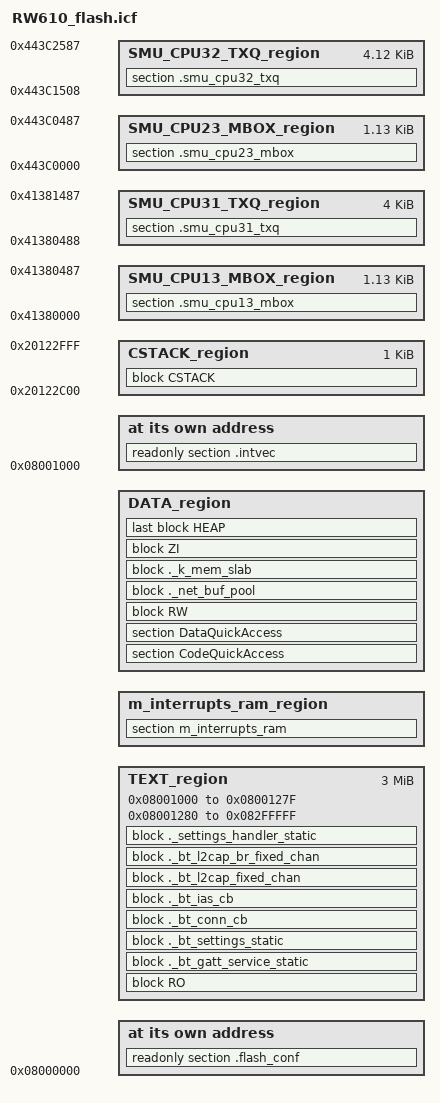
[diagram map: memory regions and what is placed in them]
/*
** ###################################################################
**     Processors:          RW612ETA2I
**                          RW612HNA2I
**                          RW612UKA2I
**
**     Compiler:            IAR ANSI C/C++ Compiler for ARM
**     Reference manual:    RW61X User manual Rev. 0.95, June 2022
**     Version:             rev. 1.0, 2021-03-16
**     Build:               b231201
**
**     Abstract:
**         Linker file for the IAR ANSI C/C++ Compiler for ARM
**
**     Copyright 2016 Freescale Semiconductor, Inc.
**     Copyright 2016-2023 NXP
**     SPDX-License-Identifier: BSD-3-Clause
**
**     http:                 www.nxp.com
**     mail:                 support@nxp.com
**
** ###################################################################
*/

/* Stack and Heap Sizes */
if (isdefinedsymbol(__stack_size__)) {
  define symbol __size_cstack__        = __stack_size__;
} else {
  define symbol __size_cstack__        = 0x0400;
}

if (isdefinedsymbol(__heap_size__)) {
  define symbol __size_heap__          = __heap_size__;
} else {
  define symbol __size_heap__          = 0x0400;
}

define symbol __ram_vector_table_size__        =  isdefinedsymbol(__ram_vector_table__) ? 0x00000280 : 0;
define symbol __ram_vector_table_offset__      =  isdefinedsymbol(__ram_vector_table__) ? 0x0000027F : 0;

define symbol m_interrupts_start               = 0x08001000;
define symbol m_interrupts_end                 = 0x0800127F;

define symbol m_text_start                     = 0x08001280;
define symbol m_text_end                       = 0x082FFFFF;

define symbol m_interrupts_ram_start           = 0x20000000;
define symbol m_interrupts_ram_end             = 0x20000000 + __ram_vector_table_offset__;

define symbol m_data_start                     = m_interrupts_ram_start + __ram_vector_table_size__;
define symbol m_data_end                       = 0x20122FFF;
/* 0x2012_3000 - 0x2012_FFFF is reserved for RW610 A1 BootROM code*/

define symbol m_boot_flash_start               = 0x08000000;

define symbol m_mbox13_start                   = 0x41380000;
define symbol m_mbox13_end                     = 0x41380487;

define symbol m_txq31_start                    = 0x41380488;
define symbol m_txq31_end                      = 0x41381487;

define symbol m_mbox23_start                   = 0x443C0000;
define symbol m_mbox23_end                     = 0x443C0487;

define symbol m_txq23_start                    = 0x443C0488;
define symbol m_txq23_end                      = 0x443C1507;

define symbol m_txq32_start                    = 0x443C1508;
define symbol m_txq32_end                      = 0x443C2587;

define exported symbol __VECTOR_TABLE          = m_interrupts_start;
define exported symbol __VECTOR_RAM            = isdefinedsymbol(__ram_vector_table__) ? m_interrupts_ram_start : m_interrupts_start;
define exported symbol __RAM_VECTOR_TABLE_SIZE = __ram_vector_table_size__;

define memory mem with size = 4G;

define symbol LITTLEFS_REGION_SIZE             = 0x00200000;

/* NOTE: The last LITTLEFS_REGION_SIZE Flash( in range (m_text_end + 1) ~ (m_text_end + LITTLEFS_REGION_SIZE)) is reserved for litteFS data */

/*** littleFS configuration Start ***/
define exported symbol EDGEFAST_BT_LITTLEFS_STORAGE_START_ADDRESS = m_text_end + 1;
define exported symbol EDGEFAST_BT_LITTLEFS_STORAGE_SECTOR_SIZE   = 0x1000;  /* 4k flash sector size */
define exported symbol EDGEFAST_BT_LITTLEFS_STORAGE_MAX_SECTORS   = LITTLEFS_REGION_SIZE / EDGEFAST_BT_LITTLEFS_STORAGE_SECTOR_SIZE;
/*** littleFS configuration End ***/

define region TEXT_region             = mem:[from m_interrupts_start to m_interrupts_end]
                                      | mem:[from m_text_start to m_text_end];
define region m_interrupts_ram_region = mem:[from m_interrupts_ram_start to m_interrupts_ram_end];
define region DATA_region             = mem:[from m_data_start to m_data_end - __size_cstack__];
define region CSTACK_region           = mem:[from m_data_end-__size_cstack__ + 1 to m_data_end];
define region SMU_CPU13_MBOX_region   = mem:[from m_mbox13_start to m_mbox13_end];
define region SMU_CPU31_TXQ_region    = mem:[from m_txq31_start to m_txq31_end];
define region SMU_CPU23_MBOX_region   = mem:[from m_mbox23_start to m_mbox23_end];
define region SMU_CPU32_TXQ_region    = mem:[from m_txq32_start to m_txq32_end];

define block CSTACK    with alignment = 8, size = __size_cstack__   { };
define block HEAP      with alignment = 8, size = __size_heap__     { };
define block RO        { readonly };
define block RW        { readwrite };
define block ZI        { zi };

initialize by copy {
  readwrite,
  section .textrw,
  section CodeQuickAccess,
  section DataQuickAccess,
  object port.o,
  object portasm.o,
  object queue.o,
  object timers.o,
  object tasks.o,
  object inet_chksum.o,
  object ip4.o,
  object pbuf.o,
  object sys_arch.o,
  object tcp_out.o,
  object tcp_in.o,
  object mlan_11n_rxreorder.o,
  object mlan_wmm.o,
  object wifi.o,
  object wifi-imu.o,
  object fsl_adapter_rfimu.o,
  object fsl_cache.o,
  object fsl_os_abstraction_free_rtos.o,
  object fsl_flexspi.o,
  object mflash_drv.o,
  object lfs.o,
  object littlefs_adapter.o
};

do not initialize  { section .noinit, section .smu_cpu13_mbox, section .smu_cpu31_txq, section .smu_cpu23_mbox, section .smu_cpu32_txq};

keep{ section .flash_conf };
place at address mem: m_boot_flash_start    { readonly section .flash_conf };
place at address mem: m_interrupts_start    { readonly section .intvec };
define block ._bt_gatt_service_static with fixed order { readonly section ._bt_gatt_service_static*};
define block ._bt_settings_static with fixed order { readonly section ._bt_settings*};
define block ._bt_conn_cb with fixed order { readonly section ._bt_conn_cb*};
define block ._bt_ias_cb with fixed order { readonly section ._bt_ias_cb*};
define block ._bt_l2cap_fixed_chan with fixed order { readonly section ._bt_l2cap_fixed_chan*};
define block ._bt_l2cap_br_fixed_chan with fixed order { readonly section ._bt_l2cap_br_fixed_chan*};
define block ._settings_handler_static with fixed order { readonly section ._settings_handler_static*};
define block ._k_mem_slab with fixed order { readwrite section ._k_mem_slab*};
define block ._net_buf_pool with fixed order { readwrite section ._net_buf_pool*};

place in TEXT_region                        { block RO, block ._bt_gatt_service_static, block ._bt_settings_static, block ._bt_conn_cb, block ._bt_ias_cb, block ._bt_l2cap_fixed_chan, block ._bt_l2cap_br_fixed_chan, block ._settings_handler_static };
place in m_interrupts_ram_region            { section m_interrupts_ram };
place in DATA_region                        { section CodeQuickAccess, section DataQuickAccess };
place in DATA_region                        { block RW, block ._net_buf_pool, block ._k_mem_slab };
place in DATA_region                        { block ZI };
place in DATA_region                        { last block HEAP };
place in CSTACK_region                      { block CSTACK };
keep { section .flash_area_list, section ._net_buf_pool*, section ._k_mem_slab*, section ._bt*, section ._settings*};

place in SMU_CPU13_MBOX_region              { section .smu_cpu13_mbox };
place in SMU_CPU31_TXQ_region               { section .smu_cpu31_txq };
place in SMU_CPU23_MBOX_region              { section .smu_cpu23_mbox };
place in SMU_CPU32_TXQ_region               { section .smu_cpu32_txq };
